# MDR1986VK01 register map
File version: 1.0.2
Registers are 32-bit, read-write, no defined reset value unless marked. A register's access mark holds for its fields unless they carry their own. Offsets are from the block's base; [hi:lo] are bit positions; {n}, {i} and the like mark numbered series; 'fields as' and 'values as' point back to an identical list.

## MDR_DMA — MDR_DMA description
Base 0xE0042000
0x00 STATUS — STATUS description
0x04 CONFIG — CONFIG description
0x08 CTRL_BASE_PTR — CTRL_BASE_PTR description
0x0C ALT_CTRL_BASE_PTR — ALT_CTRL_BASE_PTR description
0x10 WAITONREG_STATUS — WAITONREG_STATUS description
0x14 CHNL_SW_REQUEST — CHNL_SW_REQUEST description
0x18 CHNL_USEBURST_SET — CHNL_USEBURST_SET description
0x1C CHNL_USEBURST_CLR — CHNL_USEBURST_CLR description
0x20 CHNL_REQ_MASK_SET — CHNL_REQ_MASK_SET description
0x24 CHNL_REQ_MASK_CLR — CHNL_REQ_MASK_CLR description
0x28 CHNL_ENABLE_SET — CHNL_ENABLE_SET description
0x2C CHNL_ENABLE_CLR — CHNL_ENABLE_CLR description
0x30 CHNL_PRI_ALT_SET — CHNL_PRI_ALT_SET description
0x34 CHNL_PRI_ALT_CLR — CHNL_PRI_ALT_CLR description
0x38 CHNL_PRIORITY_SET — CHNL_PRIORITY_SET description
0x3C CHNL_PRIORITY_CLR — CHNL_PRIORITY_CLR description
0x4C ERR_CLR — ERR_CLR description
{0x50+4i} CHMUX{i} (i=0..7) — CHMUX{i} description

## MDR_ICACHE — MDR_ICACHE description
Base 0xE0044000
Same registers: MDR_DCACHE 0xE0045000
0x00 KEY — KEY description
0x04 CNTL — CNTL description
0x08 HIT_CNT — HIT_CNT description
0x0C MISS_CNT — MISS_CNT description
0x20 ECC_CNTL — ECC_CNTL description
0x24 ECC_ADDR — ECC_ADDR description
0x28 ECC_DATA — ECC_DATA description
0x2C ECC_ECC — ECC_ECC description

## MDR_SCR — MDR_SCR description
Base 0xE0043000
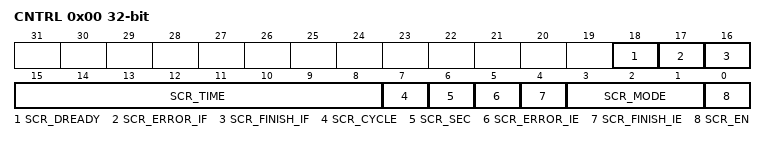
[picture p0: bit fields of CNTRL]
0x00 CNTRL — CNTRL description
  [18] SCR_DREADY, [17] SCR_ERROR_IF, [16] SCR_FINISH_IF, [15:8] SCR_TIME, [7] SCR_CYCLE, [6] SCR_SEC, [5] SCR_ERROR_IE, [4] SCR_FINISH_IE, [3:1] SCR_MODE, [0] SCR_EN
0x04 S_ADDR — S_ADDR description
0x08 F_ADDR — F_ADDR description
0x0C DATA — DATA description
0x10 ECC — ECC description
  [7:0] ECC

## MDR_ETH — MDR_ETH description
Base 0x21000000
0x00 DILIMETR 16-bit — DILIMETR description
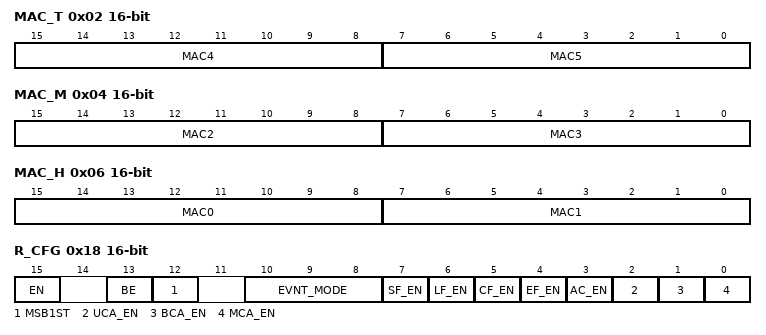
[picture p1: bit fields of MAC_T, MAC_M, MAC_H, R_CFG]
0x02 MAC_T 16-bit — MAC_T description
  [15:8] MAC4 — MAC4 description
  [7:0] MAC5 — MAC5 description
0x04 MAC_M 16-bit — MAC_M description
  [15:8] MAC2 — MAC2 description
  [7:0] MAC3 — MAC3 description
0x06 MAC_H 16-bit — MAC_H description
  [15:8] MAC0 — MAC0 description
  [7:0] MAC1 — MAC1 description
{0x8+2i} HASH{i} 16-bit (i=0..3) — HASH{i} description
0x10 ETH_IPG 16-bit — ETH_IPG description
0x12 ETH_PSC 16-bit — ETH_PSC description
0x14 ETH_BAG 16-bit — ETH_BAG description
0x16 JITTERWND 16-bit — JITTERWND description
0x18 R_CFG 16-bit — R_CFG description
  [15] EN — EN description
  [13] BE — BE description
  [12] MSB1ST — MSB1ST description
  [10:8] EVNT_MODE — EVNT_MODE description
  [7] SF_EN — SF_EN description
  [6] LF_EN — LF_EN description
  [5] CF_EN — CF_EN description
  [4] EF_EN — EF_EN description
  [3] AC_EN — AC_EN description
  [2] UCA_EN — UCA_EN description
  [1] BCA_EN — BCA_EN description
  [0] MCA_EN — MCA_EN description
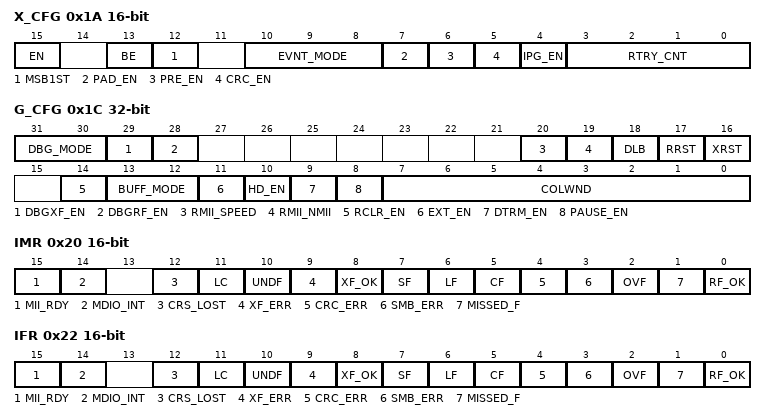
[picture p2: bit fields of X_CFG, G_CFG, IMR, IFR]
0x1A X_CFG 16-bit — X_CFG description
  [15] EN — EN description
  [13] BE — BE description
  [12] MSB1ST — MSB1ST description
  [10:8] EVNT_MODE — EVNT_MODE description
  [7] PAD_EN — PAD_EN description
  [6] PRE_EN — PRE_EN description
  [5] CRC_EN — CRC_EN description
  [4] IPG_EN — IPG_EN description
  [3:0] RTRY_CNT — RTRY_CNT description
0x1C G_CFG — G_CFG description
  [31:30] DBG_MODE — DBG_MODE description
  [29] DBGXF_EN — DBGXF_EN description
  [28] DBGRF_EN — DBGRF_EN description
  [20] RMII_SPEED — RMII_SPEED description
  [19] RMII_NMII — RMII_NMII description
  [18] DLB — DLB description
  [17] RRST — RRST description
  [16] XRST — XRST description
  [14] RCLR_EN — RCLR_EN description
  [13:12] BUFF_MODE — BUFF_MODE description
  [11] EXT_EN — EXT_EN description
  [10] HD_EN — HD_EN description
  [9] DTRM_EN — DTRM_EN description
  [8] PAUSE_EN — PAUSE_EN description
  [7:0] COLWND — COLWND description
0x20 IMR 16-bit — IMR description
  [15] MII_RDY — MII_RDY description
  [14] MDIO_INT — MDIO_INT description
  [12] CRS_LOST — CRS_LOST description
  [11] LC — LC description
  [10] UNDF — UNDF description
  [9] XF_ERR — XF_ERR description
  [8] XF_OK — XF_OK description
  [7] SF — SF description
  [6] LF — LF description
  [5] CF — CF description
  [4] CRC_ERR — CRC_ERR description
  [3] SMB_ERR — SMB_ERR description
  [2] OVF — OVF description
  [1] MISSED_F — MISSED_F description
  [0] RF_OK — RF_OK description
0x22 IFR 16-bit — IFR description
  fields as IMR
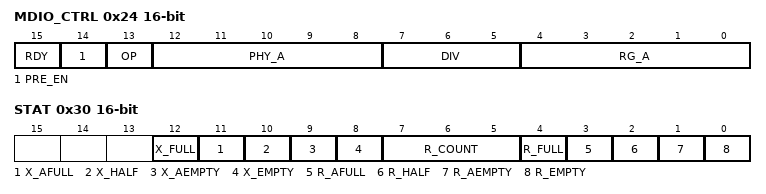
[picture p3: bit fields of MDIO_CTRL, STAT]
0x24 MDIO_CTRL 16-bit — MDIO_CTRL description
  [15] RDY — RDY description
  [14] PRE_EN — PRE_EN description
  [13] OP — OP description
  [12:8] PHY_A — PHY_A description
  [7:5] DIV — DIV description
  [4:0] RG_A — RG_A description
0x26 MDIO_DATA 16-bit — MDIO_DATA description
0x28 R_HEAD 16-bit — R_HEAD description
0x2A X_TAIL 16-bit — X_TAIL description
0x2C R_TAIL 16-bit — R_TAIL description
0x2E X_HEAD 16-bit — X_HEAD description
0x30 STAT 16-bit — STAT description
  [12] X_FULL — X_FULL description
  [11] X_AFULL — X_AFULL description
  [10] X_HALF — X_HALF description
  [9] X_AEMPTY — X_AEMPTY description
  [8] X_EMPTY — X_EMPTY description
  [7:5] R_COUNT — R_COUNT description
  [4] R_FULL — R_FULL description
  [3] R_AFULL — R_AFULL description
  [2] R_HALF — R_HALF description
  [1] R_AEMPTY — R_AEMPTY description
  [0] R_EMPTY — R_EMPTY description
0x32 RCOUNTER 16-bit — RCOUNTER description
0x34 PHY_CONTROL 16-bit — PHY_CONTROL description
0x36 PHY_STATUS 16-bit — PHY_STATUS description
0x38 PHY_CNTR_A 16-bit — PHY_CNTR_A description
